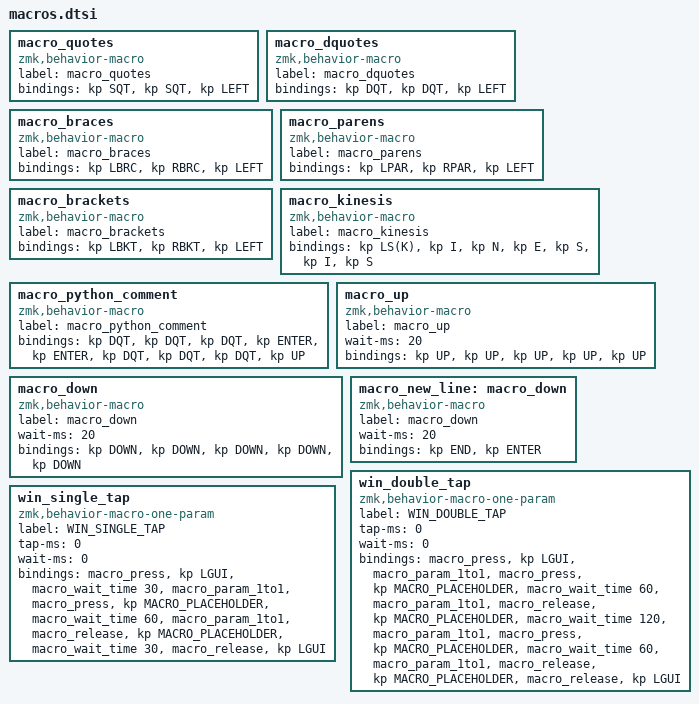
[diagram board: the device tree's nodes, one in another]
  macro_quotes: macro_quotes {
    compatible = "zmk,behavior-macro";
    label = "macro_quotes";
    #binding-cells = <0>;
    bindings = <&kp SQT>, <&kp SQT>, <&kp LEFT>;
  };
  macro_dquotes: macro_dquotes {
    compatible = "zmk,behavior-macro";
    label = "macro_dquotes";
    #binding-cells = <0>;
    bindings = <&kp DQT>, <&kp DQT>, <&kp LEFT>;
  };
  macro_braces: macro_braces {
    compatible = "zmk,behavior-macro";
    label = "macro_braces";
    #binding-cells = <0>;
    bindings = <&kp LBRC>, <&kp RBRC>, <&kp LEFT>;
  };
  macro_parens: macro_parens {
    compatible = "zmk,behavior-macro";
    label = "macro_parens";
    #binding-cells = <0>;
    bindings = <&kp LPAR>, <&kp RPAR>, <&kp LEFT>;
  };
  macro_brackets: macro_brackets {
    compatible = "zmk,behavior-macro";
    label = "macro_brackets";
    #binding-cells = <0>;
    bindings = <&kp LBKT>, <&kp RBKT>, <&kp LEFT>;
  };
  macro_kinesis: macro_kinesis {
    compatible = "zmk,behavior-macro";
    label = "macro_kinesis";
    #binding-cells = <0>;
    bindings = <&kp LS(K)>, <&kp I>, <&kp N>, <&kp E>, <&kp S>, <&kp I>, <&kp S>;
  };
  macro_python_comment: macro_python_comment {
    compatible = "zmk,behavior-macro";
    label = "macro_python_comment";
    #binding-cells = <0>;
    bindings = <&kp DQT>, <&kp DQT>, <&kp DQT>, <&kp ENTER>, <&kp ENTER>, <&kp DQT>, <&kp DQT>, <&kp DQT>, <&kp UP>;
  };
  macro_up: macro_up {
    compatible = "zmk,behavior-macro";
    label = "macro_up";
    wait-ms = <20>;
    #binding-cells = <0>;
    bindings = <&kp UP>, <&kp UP>, <&kp UP>, <&kp UP>, <&kp UP>;
  };
  macro_down: macro_down {
    compatible = "zmk,behavior-macro";
    label = "macro_down";
    wait-ms = <20>;
    #binding-cells = <0>;
    bindings = <&kp DOWN>, <&kp DOWN>, <&kp DOWN>, <&kp DOWN>, <&kp DOWN>;
  };
  macro_new_line: macro_down {
    compatible = "zmk,behavior-macro";
    label = "macro_down";
    wait-ms = <20>;
    #binding-cells = <0>;
    bindings = <&kp END>, <&kp ENTER>;
  };
  win_double_tap: win_double_tap {
    compatible = "zmk,behavior-macro-one-param";
    label = "WIN_DOUBLE_TAP";
    #binding-cells = <1>;
    tap-ms = <0>;  // Disable default tap duration since we're handling manually
    wait-ms = <0>; // Disable default wait since we're using explicit waits
    bindings = <
        &macro_press &kp LGUI
        &macro_param_1to1 &macro_press &kp MACRO_PLACEHOLDER
        &macro_wait_time 60  // Brief hold for the first "tap" to register as a press
        &macro_param_1to1 &macro_release &kp MACRO_PLACEHOLDER
        &macro_wait_time 120  // Pause between taps to ensure separation
        &macro_param_1to1 &macro_press &kp MACRO_PLACEHOLDER
        &macro_wait_time 60  // Hold for the second "tap"
        &macro_param_1to1 &macro_release &kp MACRO_PLACEHOLDER
        &macro_release &kp LGUI
    >;
  };
  win_single_tap: win_single_tap {
    compatible = "zmk,behavior-macro-one-param";
    label = "WIN_SINGLE_TAP";
    #binding-cells = <1>;
    tap-ms = <0>;
    wait-ms = <0>;
    bindings = <
        &macro_press &kp LGUI
        &macro_wait_time 30
        &macro_param_1to1 &macro_press &kp MACRO_PLACEHOLDER
        &macro_wait_time 60
        &macro_param_1to1 &macro_release &kp MACRO_PLACEHOLDER
        &macro_wait_time 30
        &macro_release &kp LGUI
    >;
  };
